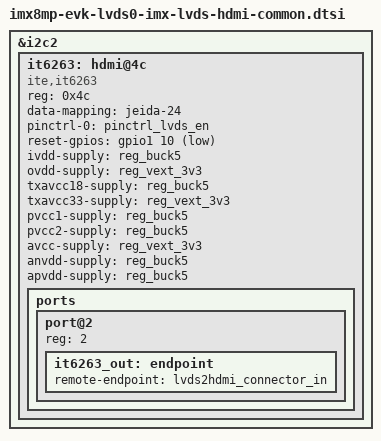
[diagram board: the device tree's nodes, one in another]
// SPDX-License-Identifier: (GPL-2.0+ OR MIT)
/*
 * Copyright 2024 NXP
 */

#include <dt-bindings/gpio/gpio.h>
#include "imx8mp-evk-imx-lvds-hdmi-common.dtsi"

&i2c2 {
	#address-cells = <1>;
	#size-cells = <0>;

	it6263: hdmi@4c {
		compatible = "ite,it6263";
		reg = <0x4c>;
		data-mapping = "jeida-24";
		pinctrl-names = "default";
		pinctrl-0 = <&pinctrl_lvds_en>;
		reset-gpios = <&gpio1 10 GPIO_ACTIVE_LOW>;
		ivdd-supply = <&reg_buck5>;
		ovdd-supply = <&reg_vext_3v3>;
		txavcc18-supply = <&reg_buck5>;
		txavcc33-supply = <&reg_vext_3v3>;
		pvcc1-supply = <&reg_buck5>;
		pvcc2-supply = <&reg_buck5>;
		avcc-supply = <&reg_vext_3v3>;
		anvdd-supply = <&reg_buck5>;
		apvdd-supply = <&reg_buck5>;

		ports {
			#address-cells = <1>;
			#size-cells = <0>;

			port@2 {
				reg = <2>;

				it6263_out: endpoint {
					remote-endpoint = <&lvds2hdmi_connector_in>;
				};
			};
		};
	};
};
